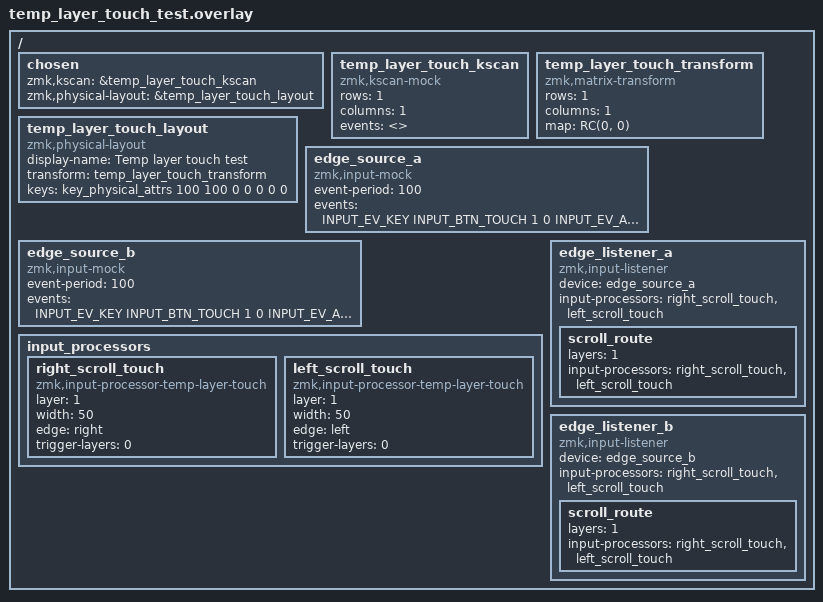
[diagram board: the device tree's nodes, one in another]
/*
 * Copyright (c) 2026 amgskobo
 * SPDX-License-Identifier: MIT
 */

#include <physical_layouts.dtsi>
#include <dt-bindings/zmk/matrix_transform.h>
#include <zephyr/dt-bindings/input/input-event-codes.h>

/ {
    chosen {
        zmk,kscan = &temp_layer_touch_kscan;
        zmk,physical-layout = &temp_layer_touch_layout;
    };

    temp_layer_touch_kscan: temp_layer_touch_kscan {
        compatible = "zmk,kscan-mock";
        rows = <1>;
        columns = <1>;
        events = <>;
    };

    temp_layer_touch_transform: temp_layer_touch_transform {
        compatible = "zmk,matrix-transform";
        rows = <1>;
        columns = <1>;
        map = <RC(0, 0)>;
    };

    temp_layer_touch_layout: temp_layer_touch_layout {
        compatible = "zmk,physical-layout";
        display-name = "Temp layer touch test";
        transform = <&temp_layer_touch_transform>;
        keys = <&key_physical_attrs 100 100 0 0 0 0 0>;
    };

    edge_source_a: edge_source_a {
        compatible = "zmk,input-mock";
        event-period = <100>;
        events = <INPUT_EV_KEY INPUT_BTN_TOUCH 1 0
                  INPUT_EV_ABS INPUT_ABS_X 1000 0
                  INPUT_EV_ABS INPUT_ABS_Y 512 1
                  INPUT_EV_KEY INPUT_BTN_TOUCH 0 1>;
    };

    edge_source_b: edge_source_b {
        compatible = "zmk,input-mock";
        event-period = <100>;
        events = <INPUT_EV_KEY INPUT_BTN_TOUCH 1 0
                  INPUT_EV_ABS INPUT_ABS_X 20 0
                  INPUT_EV_ABS INPUT_ABS_Y 512 1
                  INPUT_EV_KEY INPUT_BTN_TOUCH 0 1>;
    };

    input_processors {
        right_scroll_touch: right_scroll_touch {
            compatible = "zmk,input-processor-temp-layer-touch";
            #input-processor-cells = <0>;
            layer = <1>;
            width = <50>;
            edge = "right";
            trigger-layers = <0>;
        };

        left_scroll_touch: left_scroll_touch {
            compatible = "zmk,input-processor-temp-layer-touch";
            #input-processor-cells = <0>;
            layer = <1>;
            width = <50>;
            edge = "left";
            trigger-layers = <0>;
        };
    };

    edge_listener_a {
        compatible = "zmk,input-listener";
        device = <&edge_source_a>;
        input-processors = <&right_scroll_touch>, <&left_scroll_touch>;

        scroll_route {
            layers = <1>;
            input-processors = <&right_scroll_touch>, <&left_scroll_touch>;
        };
    };

    /* Compile-test two listener indexes sharing one stateful processor node. */
    edge_listener_b {
        compatible = "zmk,input-listener";
        device = <&edge_source_b>;
        input-processors = <&right_scroll_touch>, <&left_scroll_touch>;

        scroll_route {
            layers = <1>;
            input-processors = <&right_scroll_touch>, <&left_scroll_touch>;
        };
    };
};
